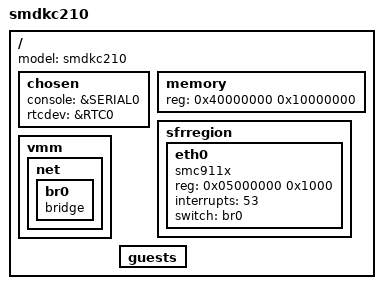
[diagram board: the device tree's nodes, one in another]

/include/ "../exynos4210.dtsi"

/ {
	model = "smdkc210";

	chosen {
		console = &SERIAL0;
		rtcdev = &RTC0;
	};

	memory {
		device_type = "memory"; 
		reg = <0x40000000 0x10000000>; /* 256 MB */
	};

	sfrregion {
		eth0 {
			device_type = "nic";
			compatible = "smc911x";
			reg = <0x05000000 0x1000>;
			interrupts = <53>;
			switch = "br0";
		};
	};

	vmm {
		net {
			br0 {
				device_type = "netswitch";
				compatible = "bridge";
			};
		};
	};

	/* Empty guests node */
	guests {
	};
};

/* Add guest templates */
/include/ "../../../common/guests/realview-pb-a8.dtsi"
/include/ "../../../common/guests/vexpress-a9x2.dtsi"

